AUTOSAR XML (schema 4-3-0)
package /org/com/c/l5
  sender receiver interface SR
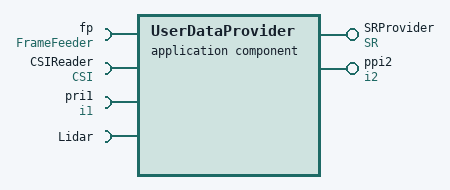
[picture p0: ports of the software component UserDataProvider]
  application sw component type UserDataProvider
    require port fp: required-interface=FrameFeeder
    require port CSIReader: required-interface=CSI
    provide port SRProvider: provided-interface=SR
    require port pri1: required-interface=i1
    provide port ppi2: provided-interface=i2
    require port Lidar: required-interface=Lidar
  client server interface CSI
package /COLLECTION
  client server interface Lidar
